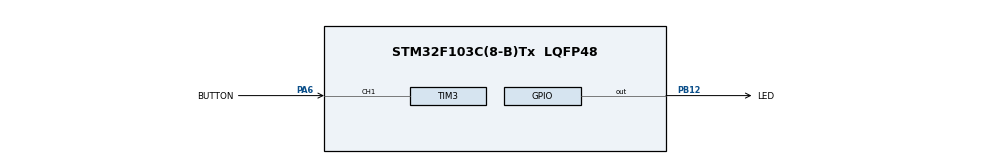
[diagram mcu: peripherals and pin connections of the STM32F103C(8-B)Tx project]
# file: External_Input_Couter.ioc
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Mcu.Family=STM32F1
Mcu.Name=STM32F103C(8-B)Tx
Mcu.Package=LQFP48
NVIC.PriorityGroup=NVIC_PRIORITYGROUP_4
PA13.Mode=Serial_Wire
PA13.Signal=SYS_JTMS-SWDIO
PA14.Mode=Serial_Wire
PA14.Signal=SYS_JTCK-SWCLK
PA6.GPIO_Label=BUTTON
PA6.GPIO_PuPd=GPIO_PULLUP
PA6.Signal=S_TIM3_CH1
PB12.GPIO_Label=LED
PB12.Signal=GPIO_Output
PD0-OSC_IN.Mode=HSE-External-Oscillator
PD0-OSC_IN.Signal=RCC_OSC_IN
PD1-OSC_OUT.Mode=HSE-External-Oscillator
PD1-OSC_OUT.Signal=RCC_OSC_OUT
ProjectManager.HeapSize=0x200
ProjectManager.StackSize=0x400
ProjectManager.TargetToolchain=MDK-ARM V5
RCC.APB1Freq_Value=8000000
RCC.APB2Freq_Value=8000000
RCC.SYSCLKSource=RCC_SYSCLKSOURCE_HSE
SH.S_TIM3_CH1.0=TIM3_CH1,TriggerSource_TI1FP1
TIM3.Period=9
VP_TIM3_VS_ControllerModeClock.Mode=Clock Mode
board=custom

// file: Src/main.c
/* USER CODE BEGIN Header */
/**
  * STM32F103C8Tx   (stm32 black pill)
	* PA6 : TIM3_CH1  Rising Edge INPUT_PULLUP .....   PA6--> BUTTON -->GND
	* PB12: OUTPUT Push pull   LED
	* external clock           8Mhz
	* -------------------------DANG VAN HAO  K57-UTC-----------------------------
  */
/* USER CODE END Header */

#include "main.h"

TIM_HandleTypeDef htim3;

/* USER CODE BEGIN PV */
int count=0;
unsigned int time=0;
/* USER CODE END PV */

void SystemClock_Config(void);
static void MX_GPIO_Init(void);
static void MX_TIM3_Init(void);

int main(void)
{

  /* MCU Configuration--------------------------------------------------------*/

  /* Reset of all peripherals, Initializes the Flash interface and the Systick. */
  HAL_Init();

  /* Configure the system clock */
  SystemClock_Config();

  /* Initialize all configured peripherals */
  MX_GPIO_Init();
  MX_TIM3_Init();
  /* USER CODE BEGIN 2 */
	HAL_TIM_Base_Start(&htim3);
  /* USER CODE END 2 */

  /* Infinite loop */
  /* USER CODE BEGIN WHILE */
  while (1)
  {
		count = __HAL_TIM_GET_COUNTER(&htim3);
		if(count ==3)
		{
			HAL_GPIO_WritePin(LED_GPIO_Port, LED_Pin, GPIO_PIN_SET);
		}
		else
			HAL_GPIO_WritePin(LED_GPIO_Port, LED_Pin, GPIO_PIN_RESET);
		HAL_Delay(100);
    /* USER CODE END WHILE */

  }
}

void SystemClock_Config(void)
{
  RCC_OscInitTypeDef RCC_OscInitStruct = {0};
  RCC_ClkInitTypeDef RCC_ClkInitStruct = {0};

  /** Initializes the CPU, AHB and APB busses clocks
  */
  RCC_OscInitStruct.OscillatorType = RCC_OSCILLATORTYPE_HSE;
  RCC_OscInitStruct.HSEState = RCC_HSE_ON;
  RCC_OscInitStruct.PLL.PLLState = RCC_PLL_NONE;
  if (HAL_RCC_OscConfig(&RCC_OscInitStruct) != HAL_OK)
  {
    Error_Handler();
  }
  /** Initializes the CPU, AHB and APB busses clocks
  */
  RCC_ClkInitStruct.ClockType = RCC_CLOCKTYPE_HCLK|RCC_CLOCKTYPE_SYSCLK
                              |RCC_CLOCKTYPE_PCLK1|RCC_CLOCKTYPE_PCLK2;
  RCC_ClkInitStruct.SYSCLKSource = RCC_SYSCLKSOURCE_HSE;
  RCC_ClkInitStruct.AHBCLKDivider = RCC_SYSCLK_DIV1;
  RCC_ClkInitStruct.APB1CLKDivider = RCC_HCLK_DIV1;
  RCC_ClkInitStruct.APB2CLKDivider = RCC_HCLK_DIV1;

  if (HAL_RCC_ClockConfig(&RCC_ClkInitStruct, FLASH_LATENCY_0) != HAL_OK)
  {
    Error_Handler();
  }
}

static void MX_TIM3_Init(void)
{

  TIM_SlaveConfigTypeDef sSlaveConfig = {0};
  TIM_MasterConfigTypeDef sMasterConfig = {0};

  htim3.Instance = TIM3;
  htim3.Init.Prescaler = 0;
  htim3.Init.CounterMode = TIM_COUNTERMODE_UP;
  htim3.Init.Period = 9;
  htim3.Init.ClockDivision = TIM_CLOCKDIVISION_DIV1;
  htim3.Init.AutoReloadPreload = TIM_AUTORELOAD_PRELOAD_DISABLE;
  if (HAL_TIM_Base_Init(&htim3) != HAL_OK)
  {
    Error_Handler();
  }
  sSlaveConfig.SlaveMode = TIM_SLAVEMODE_EXTERNAL1;
  sSlaveConfig.InputTrigger = TIM_TS_TI1FP1;
  sSlaveConfig.TriggerPolarity = TIM_TRIGGERPOLARITY_RISING;
  sSlaveConfig.TriggerFilter = 0;
  if (HAL_TIM_SlaveConfigSynchro(&htim3, &sSlaveConfig) != HAL_OK)
  {
    Error_Handler();
  }
  sMasterConfig.MasterOutputTrigger = TIM_TRGO_RESET;
  sMasterConfig.MasterSlaveMode = TIM_MASTERSLAVEMODE_DISABLE;
  if (HAL_TIMEx_MasterConfigSynchronization(&htim3, &sMasterConfig) != HAL_OK)
  {
    Error_Handler();
  }

}

static void MX_GPIO_Init(void)
{
  GPIO_InitTypeDef GPIO_InitStruct = {0};

  /* GPIO Ports Clock Enable */
  __HAL_RCC_GPIOD_CLK_ENABLE();
  __HAL_RCC_GPIOA_CLK_ENABLE();
  __HAL_RCC_GPIOB_CLK_ENABLE();

  /*Configure GPIO pin Output Level */
  HAL_GPIO_WritePin(LED_GPIO_Port, LED_Pin, GPIO_PIN_RESET);

  /*Configure GPIO pin : LED_Pin */
  GPIO_InitStruct.Pin = LED_Pin;
  GPIO_InitStruct.Mode = GPIO_MODE_OUTPUT_PP;
  GPIO_InitStruct.Pull = GPIO_NOPULL;
  GPIO_InitStruct.Speed = GPIO_SPEED_FREQ_LOW;
  HAL_GPIO_Init(LED_GPIO_Port, &GPIO_InitStruct);

}

void Error_Handler(void)
{
}

/************************ (C) COPYRIGHT STMicroelectronics *****END OF FILE****/
